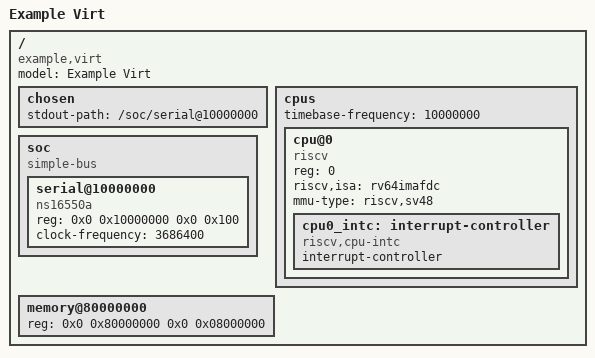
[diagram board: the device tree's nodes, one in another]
/dts-v1/;

/* A minimal QEMU 'virt'-like tree, small enough to embed into a firmware. */
/ {
    #address-cells = <2>;
    #size-cells = <2>;
    compatible = "example,virt";
    model = "Example Virt";

    chosen {
        stdout-path = "/soc/serial@10000000";
    };

    cpus {
        #address-cells = <1>;
        #size-cells = <0>;
        timebase-frequency = <10000000>;

        cpu@0 {
            device_type = "cpu";
            reg = <0>;
            compatible = "riscv";
            riscv,isa = "rv64imafdc";
            mmu-type = "riscv,sv48";

            cpu0_intc: interrupt-controller {
                #interrupt-cells = <1>;
                interrupt-controller;
                compatible = "riscv,cpu-intc";
            };
        };
    };

    soc {
        #address-cells = <2>;
        #size-cells = <2>;
        compatible = "simple-bus";
        ranges;

        serial@10000000 {
            compatible = "ns16550a";
            reg = <0x0 0x10000000 0x0 0x100>;
            clock-frequency = <3686400>;
        };
    };

    memory@80000000 {
        device_type = "memory";
        reg = <0x0 0x80000000 0x0 0x08000000>;
    };
};
